# AE8SUPERSET_CM55_HP_View register map
Vendor: Alif Semiconductor; Series: E8; File version: 1.0
CPU: CM55 r1p0, selectable endian, MPU, FPU, double-precision FPU, DSP, VTOR, 8 interrupt priority bits, 1 SAU regions
Registers are 32-bit, read-write, reset 0x0 unless marked. A register's access mark holds for its fields unless they carry their own. Offsets are from the block's base; [hi:lo] are bit positions; {n}, {i} and the like mark numbered series.

## LPCMP
Base 0x42003000
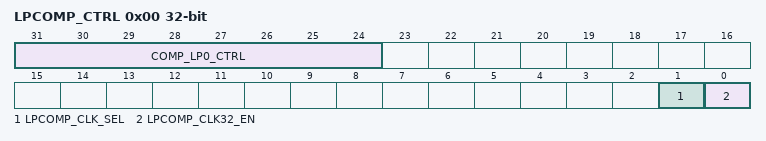
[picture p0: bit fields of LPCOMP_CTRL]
0x00 LPCOMP_CTRL — LPCMP Control Register
  [31:24] COMP_LP0_CTRL — LPCMP Control Register bit[31:29]: comp_lp0_hyst bit[28:27]: comp_lp0_in_m_sel bit[26:25]: comp_lp0_in_p_sel bit[24] : comp_lp_en (0=disable, 1=enable)
  [1] LPCOMP_CLK_SEL — LPCMP Control Register - lpcomp_clk_sel bit[1]: Select clk
  [0] LPCOMP_CLK32_EN — LPCMP Control Register - lpcomp_clk32_en bit[0]: Enable clk32 (0=disable, 1=enable)

## BOR_BOD
Base 0x42004000
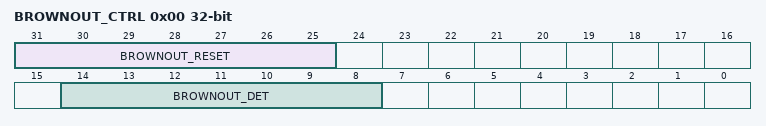
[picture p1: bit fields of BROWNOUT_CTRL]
0x00 BROWNOUT_CTRL — BOR and BOD Control Register
  [31:25] BROWNOUT_RESET — Brownout Reset Control bit[31:29] : brownout_reset_thresh bit[28:26] : brownout_reset_hyst bit[25] : brownout_reset_en (0=disable, 1=enable)
  [14:8] BROWNOUT_DET — Brownout Detect Control bit[14:12] : brownout_det_thresh bit[11:9] : brownout_det_hyst bit[8] : brownout_det_en (0=disable, 1=enable)

## LPGPIO_CTRL
Base 0x42007000
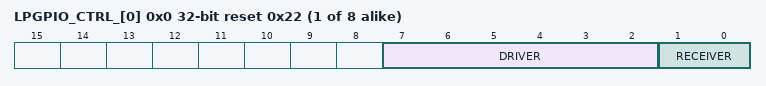
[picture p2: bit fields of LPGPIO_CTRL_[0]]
{0x0+4i} LPGPIO_CTRL_[{i}] (i=0..7) reset 0x22 — LPGPIO I/O Buffer Control Register
  [7:2] DRIVER — Driver configuration - Bit[7] selects driver mode: 0x0: Push-pull 0x1: Open drain - Bits[6-5] select driver strength: 0x0: 2 mA 0x1: 4 mA (default) 0x2: 8 mA 0x3: 12 mA - Bits[4-3] select driver disabled state: 0x0: Hi-Z 0x1: Pull-up 0x2: Pull-down 0x3: Bus keeper - Bit[2] selects slew rate: Note: Applicable only to 1.8-V I/Os (non-Flex) 0x0: Slow 0x1: Fast
  [1:0] RECEIVER — Receiver configuration - Bit[1] Schmitt trigger (hysteresis) enable: 0x0: Disabled 0x1: Enabled - Bit[0] receiver enable: 0x0: Disabled 0x1: Enabled

## LPI2C0
Base 0x43009000
0x00 LPI2C_DATA — Read/Write Data Register
  [7:0] DATA — If the corresponding FIFO is not empty/full, a byte of data can be read/written to this address. From FIFO's perspective, it would be like a pop/push operation.
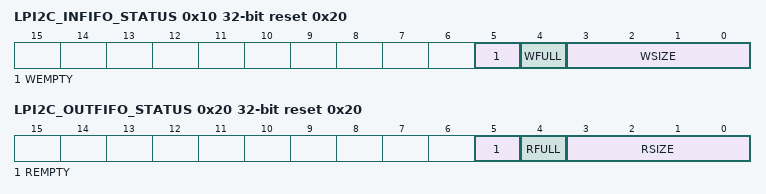
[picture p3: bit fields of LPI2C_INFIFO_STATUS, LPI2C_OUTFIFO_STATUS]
0x10 LPI2C_INFIFO_STATUS ro reset 0x20 — Inbound FIFO Status Register
  [5] WEMPTY — This field shows if the inbound FIFO is empty.
    0=Not empty; 1=Empty
  [4] WFULL — This field shows if the inbound FIFO is full.
    0=Not full; 1=Full
  [3:0] WSIZE — This field shows the number of available bytes of data in the inbound FIFO.
0x20 LPI2C_OUTFIFO_STATUS ro reset 0x20 — Outbound FIFO Status Register
  [5] REMPTY — This field shows if the outbound FIFO is empty.
    0=Not empty; 1=Empty
  [4] RFULL — This field shows if the outbound FIFO is full.
    0=Not full; 1=Full
  [3:0] RSIZE — This field shows the number of bytes of data in the outbound FIFO to be transmitted.

## CRC0
Base 0x48107000
Same registers: CRC1 0x48108000
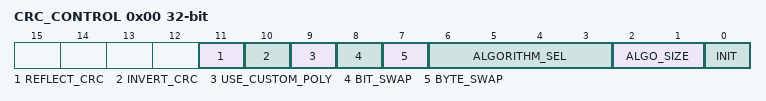
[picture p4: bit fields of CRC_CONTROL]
0x00 CRC_CONTROL — CRC Calculation Setup Register
  [11] REFLECT_CRC — Reflection of the CRC result as it is read out. An 8-bit CRC value is reflected on [7-0], bit7 to bit0, bit6 to bit1, etc. 16-bit and 32-bit CRC are reflected similarly.
    0=Reflection is disabled; 1=Reflection is enabled
  [10] INVERT_CRC — Inverting of each bit of the calculated CRC as it is read out.
    0=The CRC is not inverted; 1=Each bit is inverted
  [9] USE_CUSTOM_POLY — Use of a custom polynomial for CRC calculations. Note: Custom polynomials can only be used for 32-bit CRC algorithms.
    0=Custom polynomial is not used. The algorithm selected in CRC_CONTROL[ALGORITHM_SEL] bit field is used for the CRC calculation.; 1=Enable the use of a custom polynomial. For more information of the supported polynomials and their format, see Section CRC Overview and Section CRC Polynomials.
  [8] BIT_SWAP — Bit swapping during CRC calculation.
    0=Do not swap bits; 1=Swap the bits within each byte
  [7] BYTE_SWAP — Byte swapping during CRC calculation.
    0=Do not swap bytes; 1=Swap the bytes within each word (16-bit and 32-bit calculations only)
  [6:3] ALGORITHM_SEL — Algorithm selection.
    0=CRC-8-CCITT; 2=CRC-16; 3=CRC-16-CCITT; 4=CRC-32; 5=CRC-32C
  [2:1] ALGO_SIZE — Algorithm size selection. Must program CRC_CONTROL[ALGO_SIZE] = 0x2 when using custom polynomials.
    0=8-bit; 1=16-bit; 2=32-bit
  [0] INIT — Writing INIT will load seed and polynomial. Reading will always return INIT = 0. Bit must always be written to 0x1 before starting CRC calculations.
0x10 CRC_SEED reset 0xFFFFFFFF — Seed Value Register
  [31:0] SEED — Seed value.
0x14 CRC_POLY_CUSTOM — Custom Polynomial Register
  [31:0] CRC_POLY_CUSTOM — Bits 31-0 are used for custom 32-bit CRC calculations.
0x18 CRC_OUT ro — Accumulated CRC Register
  [31:0] CRC_OUT — Bits 31-0 are used for reading out 32-bit CRC calculations. Bits 15-0 are used for reading out 16-bit CRCs. Lowest eight bits 7-0 are used for reading out 8-bit CRCs.
{0x20+i} CRC_DATA_IN_8_[{i}] (i=0..63) 8-bit wo reset not defined — 8-bit Values Register n
  [7:0] CRC_DATA_IN_8 — Data written in this register is for 8-bit and 16-bit calculations, but only 8-bits can be written per beat.
{0x60+4i} CRC_DATA_IN_32_[{i}] (i=0..39) wo reset not defined — 32-bit Values Register n
  [31:0] CRC_DATA_IN_32 — Data written in this register is for 32-bit calculations.
